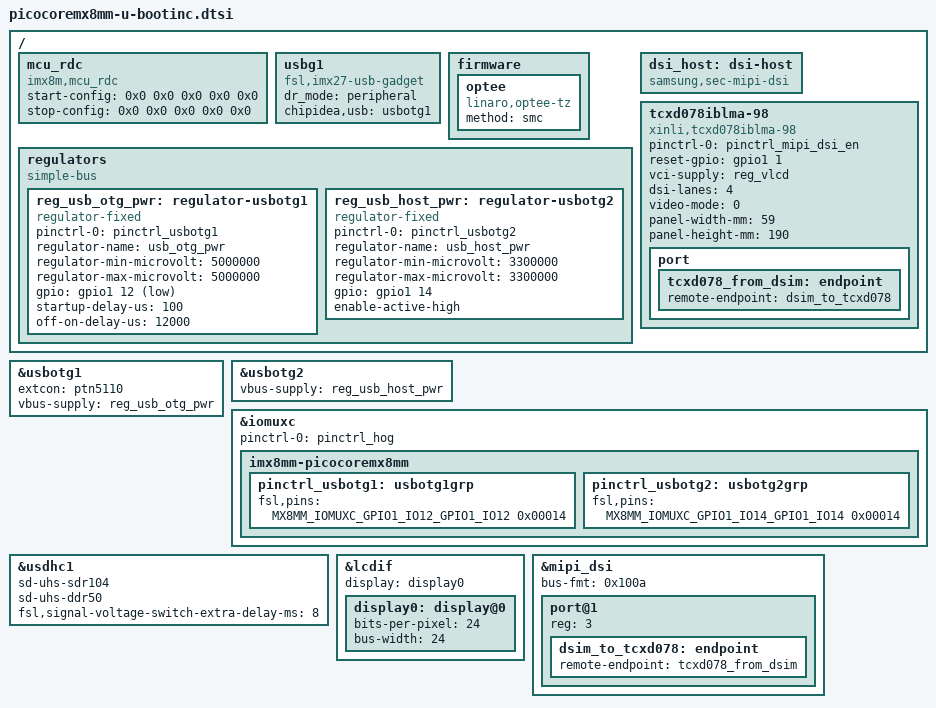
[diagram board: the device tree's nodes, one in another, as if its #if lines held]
// SPDX-License-Identifier: GPL-2.0+
/*
 * Copyright 2019 NXP
 */

/* TODO: Power polarity can't be set by DT
*  Default its low for both ports. Use regulator
*  to set pin value to correct state.
*/
/* USB0:
*  Enable regulator to activate
*  power pin for otg host devices.
*/
#define CONFIG_USB_OTG_PWR
/* USB1:
*  Enable regulator to activate power pin
*  for USB Hub.
*/
#define CONFIG_USB_HOST_PWR

/ {
	mcu_rdc {
		compatible = "imx8m,mcu_rdc";
			    /* rdc config when MCU starts
			     * master
			     *   SDMA3p --> domain 1
			     *   SDMA3b --> domain 1
			     *   SDMA3_SPBA2  --> domain 1
			     * peripheral:
			     *   SAI3   --> Only Domain 1 can access
			     *   UART4  --> Only Domain 1 can access
			     *   GPT1   --> Only Domain 1 can access
			     *   SDMA3  --> Only Domain 1 can access
			     *   I2C3   --> Only Domain 1 can access
			     * memory:
			     *   TCM    --> Only Domain 1 can access (0x7E0000~0x81FFFF)
			     *   DDR    --> Only Domain 1 can access (0x80000000~0x81000000)
			     * end.
			     */

		start-config = <
#if 0 // ### Check if these settings are correct for F&S
			    RDC_MDA  RDC_MDA_SDMA3p DID1 0x0 0x0
			    RDC_MDA  RDC_MDA_SDMA3b DID1 0x0 0x0
			    RDC_MDA  RDC_MDA_SDMA3_SPBA2 DID1 0x0 0x0
			    RDC_PDAP RDC_PDAP_SAI3  PDAP_D1_ACCESS 0x0 0x0
			    RDC_PDAP RDC_PDAP_UART4 PDAP_D1_ACCESS 0x0 0x0
			    RDC_PDAP RDC_PDAP_GPT1  PDAP_D1_ACCESS 0x0 0x0
			    RDC_PDAP RDC_PDAP_SDMA3 PDAP_D1_ACCESS 0x0 0x0
			    RDC_PDAP RDC_PDAP_I2C3  PDAP_D1_ACCESS 0x0 0x0
			    RDC_MEM_REGION 22 TCM_START TCM_END MEM_D1_ACCESS
			    RDC_MEM_REGION 39 M4_DDR_START M4_DDR_END MEM_D1_ACCESS
#endif
			    0x0      0x0            0x0  0x0 0x0
			  >;
			    /* rdc config when MCU stops
			     * memory:
			     *   TCM    --> domain 0/1 can access (0x7E0000~0x81FFFF)
			     *   DDR    --> domain 0/1 can access (0x80000000~0x81000000)
			     * end.
			     */
		stop-config = <
#if 0 // ### Check if these settings are correct for F&S
			    RDC_MEM_REGION 22 TCM_START TCM_END MEM_D0D1_ACCESS
			    RDC_MEM_REGION 39 M4_DDR_START M4_DDR_END MEM_D0D1_ACCESS
#endif
			    0x0      0x0            0x0  0x0 0x0
			  >;
	};

	usbg1: usbg1 {
		compatible = "fsl,imx27-usb-gadget";
		dr_mode = "peripheral";
		chipidea,usb = <&usbotg1>;
		status = "okay";
	};

	firmware {
		optee {
			compatible = "linaro,optee-tz";
			method = "smc";
		};
	};

	regulators {
		compatible = "simple-bus";
		#address-cells = <1>;
		#size-cells = <0>;

		#ifdef CONFIG_USB_OTG_PWR
		reg_usb_otg_pwr: regulator-usbotg1 {
			pinctrl-names = "default";
			pinctrl-0 = <&pinctrl_usbotg1>;
			compatible = "regulator-fixed";
			regulator-name = "usb_otg_pwr";
			regulator-min-microvolt = <5000000>;
			regulator-max-microvolt = <5000000>;
			gpio = <&gpio1 12 GPIO_ACTIVE_LOW>;
			startup-delay-us = <100>;
			off-on-delay-us = <12000>;
		};
		#endif
		#ifdef CONFIG_USB_HOST_PWR
		reg_usb_host_pwr: regulator-usbotg2 {
			pinctrl-names = "default";
			pinctrl-0 = <&pinctrl_usbotg2>;
			compatible = "regulator-fixed";
			regulator-name = "usb_host_pwr";
			regulator-min-microvolt = <3300000>;
			regulator-max-microvolt = <3300000>;
			gpio = <&gpio1 14 GPIO_ACTIVE_HIGH>;
			enable-active-high;
		};
		#endif
	};

#ifdef CONFIG_PICOCOREMX8MM_MIPI_DSI
	dsi_host: dsi-host {
		compatible = "samsung,sec-mipi-dsi";
		status = "okay";
	};

	tcxd078iblma-98 {
		compatible = "xinli,tcxd078iblma-98";
		pinctrl-names = "default";
		pinctrl-0 = <&pinctrl_mipi_dsi_en>;
		reset-gpio = <&gpio1 1 GPIO_ACTIVE_HIGH>;
		vci-supply = <&reg_vlcd>;
		dsi-lanes = <4>;
		video-mode = <0>;	/* 0: burst mode
					 * 1: non-burst mode with sync event
					 * 2: non-burst mode with sync pulse
					 */
		panel-width-mm = <59>;
		panel-height-mm = <190>;
		status = "okay";

		port {
			tcxd078_from_dsim: endpoint {
				remote-endpoint = <&dsim_to_tcxd078>;
			};
		};
	};

#if 0
	/* More displays ### TODO: Make them actually work */
	panel: simple_panel {
		compatible = "simple-panel";
		backlight = <&backlight_ldb>;
//###		reset-gpios = <&pca963x 3 GPIO_ACTIVE_LOW>;
//###		enable_gpios = <&pca963x 3 GPIO_ACTIVE_LOW>;
		data-mapping = "vesa-24";
		width-mm = <155>;
		height-mm = <86>;
		u-boot,dm-pre-reloc;
		port {
//###			     panel_from_lvds: endpoint {
//###				     remote-endpoint = <&lvds_to_panel>;
			lvds_from_dsim: endpoint { //### muss wieder weg
				remote-endpoint = <&dsim_to_lvds>; //### muss weg
			};
		};

		display-timings {
			bt070l1060 {
				clock-frequency = <63000000>;
				hactive = <1024>;
				vactive = <600>;
				hback-porch = <160>;
				hfront-porch = <76>;
				hsync-len = <140>;
				vback-porch = <23>;
				vfront-porch = <107>;
				vsync-len = <20>;
				pixelclk-active = <0>;
				de-active = <1>;
			};
		};
	};

	rm67199_panel {
		compatible = "raydium,rm67199";
		pinctrl-names = "default";
		pinctrl-0 = <&pinctrl_mipi_dsi_en>;
		reset-gpio = <&gpio1 8 GPIO_ACTIVE_LOW>;
		dsi-lanes = <4>;
		video-mode = <2>;	/* 0: burst mode
					 * 1: non-burst mode with sync event
					 * 2: non-burst mode with sync pulse
					 */
		panel-width-mm = <68>;
		panel-height-mm = <121>;
		status = "okay";

		port {
			rm67191_from_dsim: endpoint {
				remote-endpoint = <&dsim_to_rm67191>;
			};
		};
	};
#endif

#endif /* CONFIG_PICOCOREMX8MM_MIPI_DSI */
};


&usbotg1 {

	extcon = <&ptn5110>;
	#ifdef CONFIG_USB_OTG_PWR
	vbus-supply = <&reg_usb_otg_pwr>;
	#else
	pinctrl-names = "default";
	pinctrl-0 = <&pinctrl_usbotg1>;
	#endif
};

&usbotg2 {

	#ifdef CONFIG_USB_HOST_PWR
	vbus-supply = <&reg_usb_host_pwr>;
	#else
	pinctrl-names = "default";
	pinctrl-0 = <&pinctrl_usbotg2>;
	#endif
};

&iomuxc {
	pinctrl-names = "default";
	pinctrl-0 = <&pinctrl_hog>;

	imx8mm-picocoremx8mm {

		pinctrl_usbotg1: usbotg1grp {
			fsl,pins = <
				#ifdef CONFIG_USB_OTG_PWR
				MX8MM_IOMUXC_GPIO1_IO12_GPIO1_IO12	0x00014
				#else
				MX8MM_IOMUXC_GPIO1_IO12_USB1_OTG_PWR	0x00014
				#endif
			>;
		};

		pinctrl_usbotg2: usbotg2grp {
			fsl,pins = <
				#ifdef CONFIG_USB_HOST_PWR
				MX8MM_IOMUXC_GPIO1_IO14_GPIO1_IO14	0x00014
				#else
				MX8MM_IOMUXC_GPIO1_IO14_USB2_OTG_PWR	0x00014
				#endif
			>;
		};
	};
};

&usdhc1 {
	sd-uhs-sdr104;
	sd-uhs-ddr50;
	fsl,signal-voltage-switch-extra-delay-ms = <8>;
	/delete-property/ vqmmc-supply;
};

&lcdif {
	/delete-property/ assigned-clocks;
	/delete-property/ assigned-clock-parents;
	/delete-property/ assigned-clock-rates;

	display = <&display0>;

	display0: display@0 {
		bits-per-pixel = <24>;
		bus-width = <24>;
	};
};

#ifdef CONFIG_PICOCOREMX8MM_MIPI_DSI
&mipi_dsi {
	/delete-property/ assigned-clocks;
	/delete-property/ assigned-clock-parents;
	/delete-property/ assigned-clock-rates;

	status = "okay";
	bus-fmt = <0x100a>;
	port@1 {
		reg = <3>;
		dsim_to_tcxd078: endpoint {
			remote-endpoint = <&tcxd078_from_dsim>;
		};
	};

#if 0
	/* More displays ### TODO: make them actually work */
	port@2 {
		reg = <1>;
		dsim_to_lvds: endpoint {
			remote-endpoint = <&lvds_from_dsim>;
			data-lanes = <0 1 2 3>;
			attach-bridge;
		};
	};

	port@3 {
		reg = <2>;
		dsim_to_rm67191: endpoint {
			remote-endpoint = <&rm67191_from_dsim>;
		};
	};
#endif
};

#if 0 //###
&i2c4 {
	tc358775@f {
		compatible = "toshiba,tc358775";
		reg = <0x0f>;
		pinctrl-names = "default";
//###		pinctrl-0 = <&pinctrl_mipi_dsi_lvds_en>;
		vdd-supply = <&reg_vref_1v8>;
		vddio-supply = <&reg_vref_3v3>;

//###                reset-gpios = <&IMX8MM_LVDS_RESET_GPIO_BANK IMX8MM_LVDS_RESET_GPIO_NUM GPIO_ACTIVE_LOW>;
#ifdef IMX8MM_LVDS_STBY_GPIO_BANK
//###                stby-gpios  = <&IMX8MM_LVDS_STBY_GPIO_BANK IMX8MM_LVDS_STBY_GPIO_NUM GPIO_ACTIVE_LOW>;
#endif
		ports {
			#address-cells = <1>;
			#size-cells = <0>;

			port@0 {
				reg = <0>;

				lvds_from_dsim: endpoint {
					remote-endpoint = <&dsim_to_lvds>;
				};
			};

			port@1 {
				reg = <1>;

				lvds_to_panel: endpoint {
					remote-endpoint = <&panel_from_lvds>;
				};
			};
		};
	};
};
#endif

#endif /* CONFIG_PICOCOREMX8MM_MIPI_DSI */
